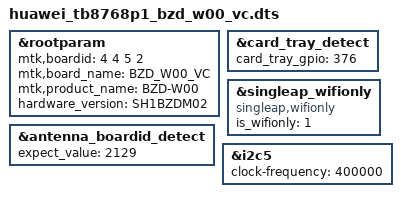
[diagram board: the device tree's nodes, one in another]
#include <dt-bindings/interrupt-controller/arm-gic.h>
#include <dt-bindings/interrupt-controller/irq.h>
#include <dt-bindings/pinctrl/mt6765-pinfunc.h>
#include <dt-bindings/clock/mt6765-clk.h>
/dts-v1/;
/plugin/;

#include "huawei_common/huawei_common.dtsi"
#include "huawei_tb8768p1_bzd_w00_vc/huawei.dtsi"

&rootparam {
    mtk,boardid = <4 4 5 2>;
    mtk,board_name = "BZD_W00_VC";
    mtk,product_name = "BZD-W00";
    hardware_version = "SH1BZDM02";
};

&antenna_boardid_detect {
    expect_value = <2129>;
};

&card_tray_detect {
    card_tray_gpio = <376>;
};

&singleap_wifionly {
    compatible = "singleap,wifionly";
    status = "okay";
    is_wifionly = "1";
};

#include <tb8768p1_64_a32/cust.dtsi>
#include "huawei_tb8768p1_bzd_w00_vc/huawei-camera.dtsi"
&i2c5 {
	clock-frequency = <400000>;
};
/*End of this file, DO NOT ADD ANYTHING HERE*/

